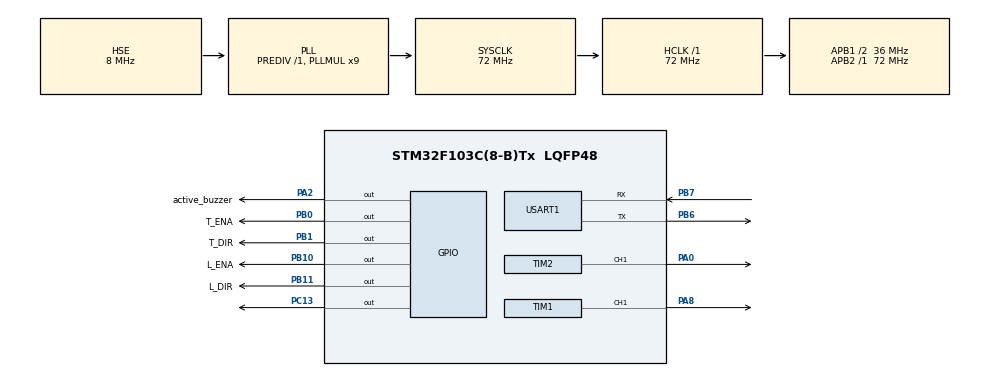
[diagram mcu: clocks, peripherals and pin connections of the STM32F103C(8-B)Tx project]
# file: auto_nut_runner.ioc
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Mcu.Family=STM32F1
Mcu.Name=STM32F103C(8-B)Tx
Mcu.Package=LQFP48
NVIC.PriorityGroup=NVIC_PRIORITYGROUP_4
NVIC.TIM1_BRK_IRQn=true\:0\:0\:false\:false\:true\:true\:true\:true
NVIC.TIM1_UP_IRQn=true\:0\:0\:false\:false\:true\:true\:true\:true
NVIC.TIM2_IRQn=true\:0\:0\:false\:false\:true\:true\:true\:true
NVIC.USART1_IRQn=true\:0\:0\:false\:false\:true\:true\:true\:true
PA0-WKUP.Signal=S_TIM2_CH1_ETR
PA13.Mode=Serial_Wire
PA13.Signal=SYS_JTMS-SWDIO
PA14.Mode=Serial_Wire
PA14.Signal=SYS_JTCK-SWCLK
PA2.GPIO_Label=active_buzzer
PA2.GPIO_ModeDefaultOutputPP=GPIO_MODE_OUTPUT_OD
PA2.GPIO_PuPd=GPIO_NOPULL
PA2.PinState=GPIO_PIN_SET
PA2.Signal=GPIO_Output
PA8.Signal=S_TIM1_CH1
PB0.GPIO_Label=T_ENA
PB0.GPIO_ModeDefaultOutputPP=GPIO_MODE_OUTPUT_PP
PB0.GPIO_PuPd=GPIO_NOPULL
PB0.PinState=GPIO_PIN_SET
PB0.Signal=GPIO_Output
PB1.GPIO_Label=T_DIR
PB1.GPIO_ModeDefaultOutputPP=GPIO_MODE_OUTPUT_PP
PB1.GPIO_PuPd=GPIO_NOPULL
PB1.PinState=GPIO_PIN_SET
PB1.Signal=GPIO_Output
PB10.GPIO_Label=L_ENA
PB10.GPIO_ModeDefaultOutputPP=GPIO_MODE_OUTPUT_PP
PB10.GPIO_PuPd=GPIO_NOPULL
PB10.Signal=GPIO_Output
PB11.GPIO_Label=L_DIR
PB11.GPIO_ModeDefaultOutputPP=GPIO_MODE_OUTPUT_PP
PB11.GPIO_PuPd=GPIO_NOPULL
PB11.PinState=GPIO_PIN_SET
PB11.Signal=GPIO_Output
PB6.Mode=Asynchronous
PB6.Signal=USART1_TX
PB7.Mode=Asynchronous
PB7.Signal=USART1_RX
PC13-TAMPER-RTC.GPIO_ModeDefaultOutputPP=GPIO_MODE_OUTPUT_OD
PC13-TAMPER-RTC.GPIO_PuPd=GPIO_NOPULL
PC13-TAMPER-RTC.GPIO_Speed=GPIO_SPEED_FREQ_MEDIUM
PC13-TAMPER-RTC.PinState=GPIO_PIN_SET
PC13-TAMPER-RTC.Signal=GPIO_Output
PD0-OSC_IN.Mode=HSE-External-Oscillator
PD0-OSC_IN.Signal=RCC_OSC_IN
PD1-OSC_OUT.Mode=HSE-External-Oscillator
PD1-OSC_OUT.Signal=RCC_OSC_OUT
ProjectManager.HeapSize=0x200
ProjectManager.StackSize=0x400
ProjectManager.TargetToolchain=Makefile
RCC.AHBFreq_Value=72000000
RCC.APB1CLKDivider=RCC_HCLK_DIV2
RCC.APB1Freq_Value=36000000
RCC.APB1TimFreq_Value=72000000
RCC.APB2Freq_Value=72000000
RCC.APB2TimFreq_Value=72000000
RCC.HCLKFreq_Value=72000000
RCC.PLLMUL=RCC_PLL_MUL9
RCC.PLLSourceVirtual=RCC_PLLSOURCE_HSE
RCC.SYSCLKFreq_VALUE=72000000
RCC.SYSCLKSource=RCC_SYSCLKSOURCE_PLLCLK
RCC.USBFreq_Value=72000000
SH.S_TIM1_CH1.0=TIM1_CH1,PWM Generation1 CH1
SH.S_TIM2_CH1_ETR.0=TIM2_CH1,PWM Generation1 CH1
TIM1.AutoReloadPreload=TIM_AUTORELOAD_PRELOAD_ENABLE
TIM1.Channel-PWM\ Generation1\ CH1=TIM_CHANNEL_1
TIM1.Period=1000-1
TIM1.Prescaler=72-1
TIM1.Pulse-PWM\ Generation1\ CH1=1000/2
TIM1.RepetitionCounter=0
TIM2.AutoReloadPreload=TIM_AUTORELOAD_PRELOAD_ENABLE
TIM2.Channel-PWM\ Generation1\ CH1=TIM_CHANNEL_1
TIM2.Period=1000-1
TIM2.Prescaler=72-1
TIM2.Pulse-PWM\ Generation1\ CH1=1000/2
USART1.VirtualMode=VM_ASYNC
VP_TIM1_VS_ClockSourceINT.Mode=Internal
VP_TIM2_VS_ClockSourceINT.Mode=Internal
board=custom

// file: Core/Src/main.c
/* USER CODE BEGIN Header */
/**
  ******************************************************************************
  * @file           : main.c
  * @brief          : Main program body
  ******************************************************************************
  * @attention
  *
  * Copyright (c) 2025 STMicroelectronics.
  * All rights reserved.
  *
  * This software is licensed under terms that can be found in the LICENSE file
  * in the root directory of this software component.
  * If no LICENSE file comes with this software, it is provided AS-IS.
  *
  ******************************************************************************
  */
/* USER CODE END Header */
#include "main.h"

/* USER CODE BEGIN Includes */
#include <stdio.h>
#include "config.h"
#include "cmd_handler.h"
#include "led.h"
#include "stepper.h"
#include "gear_motor.h"

/* USER CODE END Includes */

TIM_HandleTypeDef htim1;
TIM_HandleTypeDef htim2;

UART_HandleTypeDef huart1;

/* USER CODE BEGIN PV */
#define RX_BUFFER_SIZE 128				// 接受缓冲区的大小
#define CMD_MAX_SIZE 64					// 指令最大长度
volatile uint8_t rx_buffer;				// 接收缓冲区
volatile char command[CMD_MAX_SIZE];	// 存储完整指令
volatile uint8_t rx_index = 0;			// 缓冲区索引
volatile uint8_t cmd_received = 0;

stepper_t turntable;	// 转台步进电机
stepper_t lifter;		// 升降步进电机
gear_motor_t gear_motor;	// 拧螺丝电机
/* USER CODE END PV */

void SystemClock_Config(void);
static void MX_GPIO_Init(void);
static void MX_TIM1_Init(void);
static void MX_USART1_UART_Init(void);
static void MX_TIM2_Init(void);

int main(void)
{

  /* USER CODE BEGIN 1 */
	// 开启AFIO时钟并重映射USART1到PB6, PB7
  __HAL_RCC_AFIO_CLK_ENABLE();
  __HAL_AFIO_REMAP_USART1_ENABLE();
  /* USER CODE END 1 */

  /* MCU Configuration--------------------------------------------------------*/

  /* Reset of all peripherals, Initializes the Flash interface and the Systick. */
  HAL_Init();

  /* Configure the system clock */
  SystemClock_Config();

  /* Initialize all configured peripherals */
  MX_GPIO_Init();
  MX_TIM1_Init();
  MX_USART1_UART_Init();
  MX_TIM2_Init();
  /* USER CODE BEGIN 2 */
  	// 启动串口接收中断
	HAL_UART_Receive_IT(&huart1, (uint8_t*)&rx_buffer, 1);	// 启动第1次接收

	// 电机初始化
	stepper_init(&turntable, &htim1, STP_T_CHANNEL, STP_T_ENA_PORT, STP_T_ENA_PIN, STP_T_DIR_PORT, STP_T_DIR_PIN);
	stepper_init(&lifter, &htim2, STP_L_CHANNEL, STP_L_ENA_PORT, STP_L_ENA_PIN, STP_L_DIR_PORT, STP_L_DIR_PIN);
	stepper_set_arr(&turntable, 1000-1); // 自动重装寄存器，设置脉冲周期，影响脉冲发送频率快慢，即步进电机速度快慢
	stepper_set_arr(&lifter, 1000-1);
	UNUSED(gear_motor);

	HAL_TIM_Base_Start_IT(&htim1); // 启动转台定时器中断
	HAL_TIM_Base_Start_IT(&htim2); // 启动升降定时器中断
  /* USER CODE END 2 */

  /* Infinite loop */
  /* USER CODE BEGIN WHILE */
  while (1)
  {
	  if(cmd_received){	// 检测到新指令
		  cmd_received = 0;	// 清除标志位
		  cmd_dispatcher((const char*)command);	// 解析并执行指令
		  rx_index = 0; // 重置索引
	  }
    /* USER CODE END WHILE */

  }
}

void SystemClock_Config(void)
{
  RCC_OscInitTypeDef RCC_OscInitStruct = {0};
  RCC_ClkInitTypeDef RCC_ClkInitStruct = {0};

  /** Initializes the RCC Oscillators according to the specified parameters
  * in the RCC_OscInitTypeDef structure.
  */
  RCC_OscInitStruct.OscillatorType = RCC_OSCILLATORTYPE_HSE;
  RCC_OscInitStruct.HSEState = RCC_HSE_ON;
  RCC_OscInitStruct.HSEPredivValue = RCC_HSE_PREDIV_DIV1;
  RCC_OscInitStruct.HSIState = RCC_HSI_ON;
  RCC_OscInitStruct.PLL.PLLState = RCC_PLL_ON;
  RCC_OscInitStruct.PLL.PLLSource = RCC_PLLSOURCE_HSE;
  RCC_OscInitStruct.PLL.PLLMUL = RCC_PLL_MUL9;
  if (HAL_RCC_OscConfig(&RCC_OscInitStruct) != HAL_OK)
  {
    Error_Handler();
  }

  /** Initializes the CPU, AHB and APB buses clocks
  */
  RCC_ClkInitStruct.ClockType = RCC_CLOCKTYPE_HCLK|RCC_CLOCKTYPE_SYSCLK
                              |RCC_CLOCKTYPE_PCLK1|RCC_CLOCKTYPE_PCLK2;
  RCC_ClkInitStruct.SYSCLKSource = RCC_SYSCLKSOURCE_PLLCLK;
  RCC_ClkInitStruct.AHBCLKDivider = RCC_SYSCLK_DIV1;
  RCC_ClkInitStruct.APB1CLKDivider = RCC_HCLK_DIV2;
  RCC_ClkInitStruct.APB2CLKDivider = RCC_HCLK_DIV1;

  if (HAL_RCC_ClockConfig(&RCC_ClkInitStruct, FLASH_LATENCY_2) != HAL_OK)
  {
    Error_Handler();
  }
}

static void MX_TIM1_Init(void)
{

  TIM_ClockConfigTypeDef sClockSourceConfig = {0};
  TIM_MasterConfigTypeDef sMasterConfig = {0};
  TIM_OC_InitTypeDef sConfigOC = {0};
  TIM_BreakDeadTimeConfigTypeDef sBreakDeadTimeConfig = {0};

  htim1.Instance = TIM1;
  htim1.Init.Prescaler = 72-1;
  htim1.Init.CounterMode = TIM_COUNTERMODE_UP;
  htim1.Init.Period = 1000-1;
  htim1.Init.ClockDivision = TIM_CLOCKDIVISION_DIV1;
  htim1.Init.RepetitionCounter = 0;
  htim1.Init.AutoReloadPreload = TIM_AUTORELOAD_PRELOAD_ENABLE;
  if (HAL_TIM_Base_Init(&htim1) != HAL_OK)
  {
    Error_Handler();
  }
  sClockSourceConfig.ClockSource = TIM_CLOCKSOURCE_INTERNAL;
  if (HAL_TIM_ConfigClockSource(&htim1, &sClockSourceConfig) != HAL_OK)
  {
    Error_Handler();
  }
  if (HAL_TIM_PWM_Init(&htim1) != HAL_OK)
  {
    Error_Handler();
  }
  sMasterConfig.MasterOutputTrigger = TIM_TRGO_RESET;
  sMasterConfig.MasterSlaveMode = TIM_MASTERSLAVEMODE_DISABLE;
  if (HAL_TIMEx_MasterConfigSynchronization(&htim1, &sMasterConfig) != HAL_OK)
  {
    Error_Handler();
  }
  sConfigOC.OCMode = TIM_OCMODE_PWM1;
  sConfigOC.Pulse = 1000/2;
  sConfigOC.OCPolarity = TIM_OCPOLARITY_HIGH;
  sConfigOC.OCNPolarity = TIM_OCNPOLARITY_HIGH;
  sConfigOC.OCFastMode = TIM_OCFAST_DISABLE;
  sConfigOC.OCIdleState = TIM_OCIDLESTATE_RESET;
  sConfigOC.OCNIdleState = TIM_OCNIDLESTATE_RESET;
  if (HAL_TIM_PWM_ConfigChannel(&htim1, &sConfigOC, TIM_CHANNEL_1) != HAL_OK)
  {
    Error_Handler();
  }
  sBreakDeadTimeConfig.OffStateRunMode = TIM_OSSR_DISABLE;
  sBreakDeadTimeConfig.OffStateIDLEMode = TIM_OSSI_DISABLE;
  sBreakDeadTimeConfig.LockLevel = TIM_LOCKLEVEL_OFF;
  sBreakDeadTimeConfig.DeadTime = 0;
  sBreakDeadTimeConfig.BreakState = TIM_BREAK_DISABLE;
  sBreakDeadTimeConfig.BreakPolarity = TIM_BREAKPOLARITY_HIGH;
  sBreakDeadTimeConfig.AutomaticOutput = TIM_AUTOMATICOUTPUT_DISABLE;
  if (HAL_TIMEx_ConfigBreakDeadTime(&htim1, &sBreakDeadTimeConfig) != HAL_OK)
  {
    Error_Handler();
  }
  HAL_TIM_MspPostInit(&htim1);

}

static void MX_TIM2_Init(void)
{

  TIM_ClockConfigTypeDef sClockSourceConfig = {0};
  TIM_MasterConfigTypeDef sMasterConfig = {0};
  TIM_OC_InitTypeDef sConfigOC = {0};

  htim2.Instance = TIM2;
  htim2.Init.Prescaler = 72-1;
  htim2.Init.CounterMode = TIM_COUNTERMODE_UP;
  htim2.Init.Period = 1000-1;
  htim2.Init.ClockDivision = TIM_CLOCKDIVISION_DIV1;
  htim2.Init.AutoReloadPreload = TIM_AUTORELOAD_PRELOAD_ENABLE;
  if (HAL_TIM_Base_Init(&htim2) != HAL_OK)
  {
    Error_Handler();
  }
  sClockSourceConfig.ClockSource = TIM_CLOCKSOURCE_INTERNAL;
  if (HAL_TIM_ConfigClockSource(&htim2, &sClockSourceConfig) != HAL_OK)
  {
    Error_Handler();
  }
  if (HAL_TIM_PWM_Init(&htim2) != HAL_OK)
  {
    Error_Handler();
  }
  sMasterConfig.MasterOutputTrigger = TIM_TRGO_RESET;
  sMasterConfig.MasterSlaveMode = TIM_MASTERSLAVEMODE_DISABLE;
  if (HAL_TIMEx_MasterConfigSynchronization(&htim2, &sMasterConfig) != HAL_OK)
  {
    Error_Handler();
  }
  sConfigOC.OCMode = TIM_OCMODE_PWM1;
  sConfigOC.Pulse = 1000/2;
  sConfigOC.OCPolarity = TIM_OCPOLARITY_HIGH;
  sConfigOC.OCFastMode = TIM_OCFAST_DISABLE;
  if (HAL_TIM_PWM_ConfigChannel(&htim2, &sConfigOC, TIM_CHANNEL_1) != HAL_OK)
  {
    Error_Handler();
  }
  HAL_TIM_MspPostInit(&htim2);

}

static void MX_USART1_UART_Init(void)
{

  huart1.Instance = USART1;
  huart1.Init.BaudRate = 115200;
  huart1.Init.WordLength = UART_WORDLENGTH_8B;
  huart1.Init.StopBits = UART_STOPBITS_1;
  huart1.Init.Parity = UART_PARITY_NONE;
  huart1.Init.Mode = UART_MODE_TX_RX;
  huart1.Init.HwFlowCtl = UART_HWCONTROL_NONE;
  huart1.Init.OverSampling = UART_OVERSAMPLING_16;
  if (HAL_UART_Init(&huart1) != HAL_OK)
  {
    Error_Handler();
  }

}

static void MX_GPIO_Init(void)
{
  GPIO_InitTypeDef GPIO_InitStruct = {0};

  /* GPIO Ports Clock Enable */
  __HAL_RCC_GPIOC_CLK_ENABLE();
  __HAL_RCC_GPIOD_CLK_ENABLE();
  __HAL_RCC_GPIOA_CLK_ENABLE();
  __HAL_RCC_GPIOB_CLK_ENABLE();

  /*Configure GPIO pin Output Level */
  HAL_GPIO_WritePin(GPIOC, GPIO_PIN_13, GPIO_PIN_SET);

  /*Configure GPIO pin Output Level */
  HAL_GPIO_WritePin(buzzer_GPIO_Port, buzzer_Pin, GPIO_PIN_SET);

  /*Configure GPIO pin Output Level */
  HAL_GPIO_WritePin(GPIOB, T_ENA_Pin|T_DIR_Pin|L_DIR_Pin, GPIO_PIN_SET);

  /*Configure GPIO pin Output Level */
  HAL_GPIO_WritePin(L_ENA_GPIO_Port, L_ENA_Pin, GPIO_PIN_RESET);

  /*Configure GPIO pin : PC13 */
  GPIO_InitStruct.Pin = GPIO_PIN_13;
  GPIO_InitStruct.Mode = GPIO_MODE_OUTPUT_OD;
  GPIO_InitStruct.Pull = GPIO_NOPULL;
  GPIO_InitStruct.Speed = GPIO_SPEED_FREQ_MEDIUM;
  HAL_GPIO_Init(GPIOC, &GPIO_InitStruct);

  /*Configure GPIO pin : buzzer_Pin */
  GPIO_InitStruct.Pin = buzzer_Pin;
  GPIO_InitStruct.Mode = GPIO_MODE_OUTPUT_OD;
  GPIO_InitStruct.Pull = GPIO_NOPULL;
  GPIO_InitStruct.Speed = GPIO_SPEED_FREQ_LOW;
  HAL_GPIO_Init(buzzer_GPIO_Port, &GPIO_InitStruct);

  /*Configure GPIO pins : T_ENA_Pin T_DIR_Pin L_ENA_Pin L_DIR_Pin */
  GPIO_InitStruct.Pin = T_ENA_Pin|T_DIR_Pin|L_ENA_Pin|L_DIR_Pin;
  GPIO_InitStruct.Mode = GPIO_MODE_OUTPUT_PP;
  GPIO_InitStruct.Pull = GPIO_NOPULL;
  GPIO_InitStruct.Speed = GPIO_SPEED_FREQ_LOW;
  HAL_GPIO_Init(GPIOB, &GPIO_InitStruct);

}

/* USER CODE BEGIN 4 */
/**
 * @brief 实现串口接收中断回调函数
 *
 */
void HAL_UART_RxCpltCallback(UART_HandleTypeDef *huart) {
    if(huart->Instance == USART1) {
        if(rx_buffer == '$') { // 检测指令结束符（$）
            if(rx_index > 0) {
                command[rx_index] = '\0';  // 添加字符串结束符
                cmd_received = 1;          // 设置指令接收标志
            }
            rx_index = 0;  // 重置索引
        } else if (rx_index < (CMD_MAX_SIZE - 1)) { // 处理正常字符
            command[rx_index++] = rx_buffer;
        } else { // 缓冲区溢出处理
            rx_index = 0;  // 重置索引
            command[0] = '\0';
        }

        // 重新启动接收中断，等待下一个字节
        HAL_UART_Receive_IT(huart, (uint8_t*)&rx_buffer, 1);
    }
}
/**
 * @brief 实现定时器中断回调函数
 */
void HAL_TIM_PeriodElapsedCallback(TIM_HandleTypeDef *htim){
    // 转台电机中断
    if(htim == turntable.htim){
        stepper_update_callback(&turntable);
    }
    // 升降电机中断
    else if(htim == lifter.htim){
        stepper_update_callback(&lifter);
    }

}
/* USER CODE END 4 */

void Error_Handler(void)
{
  __disable_irq();
  while (1)
  {
  }
}
